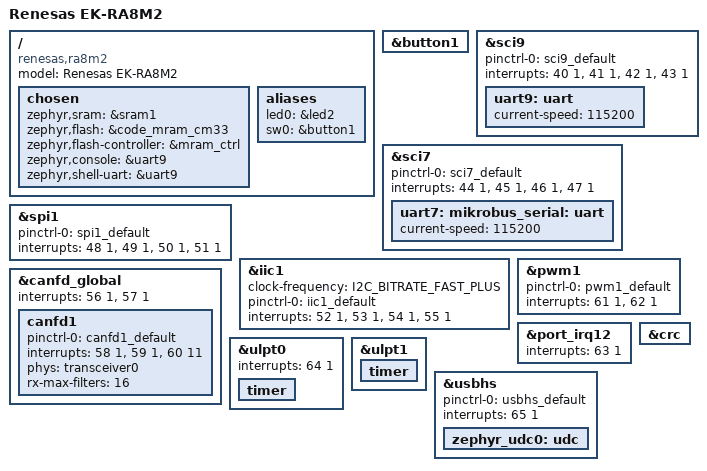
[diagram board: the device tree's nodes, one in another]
/*
 * Copyright (c) 2026 Renesas Electronics Corporation
 * SPDX-License-Identifier: Apache-2.0
 */

/dts-v1/;

#include <renesas/ra/ra8/r7ka8m2jflcac_cm33.dtsi>
#include "ek_ra8m2.dtsi"

/ {
	model = "Renesas EK-RA8M2";
	compatible = "renesas,ra8m2", "renesas,ra8";

	chosen {
		zephyr,sram = &sram1;
		zephyr,flash = &code_mram_cm33;
		zephyr,flash-controller = &mram_ctrl;
		zephyr,console = &uart9;
		zephyr,shell-uart = &uart9;
	};

	aliases {
		led0 = &led2;
		sw0 = &button1;
	};
};

&button1 {
	status = "okay";
};

&sci9 {
	pinctrl-0 = <&sci9_default>;
	pinctrl-names = "default";
	interrupts = <40 1>, <41 1>, <42 1>, <43 1>;
	interrupt-names = "rxi", "txi", "tei", "eri";
	status = "okay";

	uart9: uart {
		current-speed = <115200>;
		status = "okay";
	};
};

&sci7 {
	pinctrl-0 = <&sci7_default>;
	pinctrl-names = "default";
	interrupts = <44 1>, <45 1>, <46 1>, <47 1>;
	interrupt-names = "rxi", "txi", "tei", "eri";
	status = "okay";

	uart7: uart {
		current-speed = <115200>;
	};
};

&spi1 {
	pinctrl-0 = <&spi1_default>;
	pinctrl-names = "default";
	interrupts = <48 1>, <49 1>, <50 1>, <51 1>;
	interrupt-names = "rxi", "txi", "tei", "eri";
};

&iic1 {
	#address-cells = <1>;
	#size-cells = <0>;
	clock-frequency = <I2C_BITRATE_FAST_PLUS>;
	pinctrl-0 = <&iic1_default>;
	pinctrl-names = "default";
	interrupts = <52 1>, <53 1>, <54 1>, <55 1>;
	interrupt-names = "rxi", "txi", "tei", "eri";
};

&canfd_global {
	interrupts = <56 1>, <57 1>;
	interrupt-names = "rxf", "glerr";
	status = "okay";

	canfd1 {
		pinctrl-0 = <&canfd1_default>;
		pinctrl-names = "default";
		interrupts = <58 1>, <59 1>, <60 11>;
		interrupt-names = "err", "tx", "rx";
		phys = <&transceiver0>;
		rx-max-filters = <16>;
		status = "okay";
	};
};

&pwm1 {
	pinctrl-0 = <&pwm1_default>;
	interrupts = <61 1>, <62 1>;
	interrupt-names = "gtioca", "overflow";
	pinctrl-names = "default";
	status = "okay";
};

&port_irq12 {
	interrupts = <63 1>;
	status = "okay";
};

&ulpt0 {
	interrupts = <64 1>;
	interrupt-names = "ulpti";
	status = "okay";

	timer {
		status = "okay";
	};
};

&ulpt1 {
	status = "okay";

	timer {
		status = "okay";
	};
};

&crc {
	status = "okay";
};

&usbhs {
	pinctrl-0 = <&usbhs_default>;
	interrupts = <65 1>;
	interrupt-names = "usbhs-ir";
	status = "okay";

	zephyr_udc0: udc {
		status = "okay";
	};
};

mikrobus_serial: &uart7 {};

mikrobus_spi: &spi1 {};
